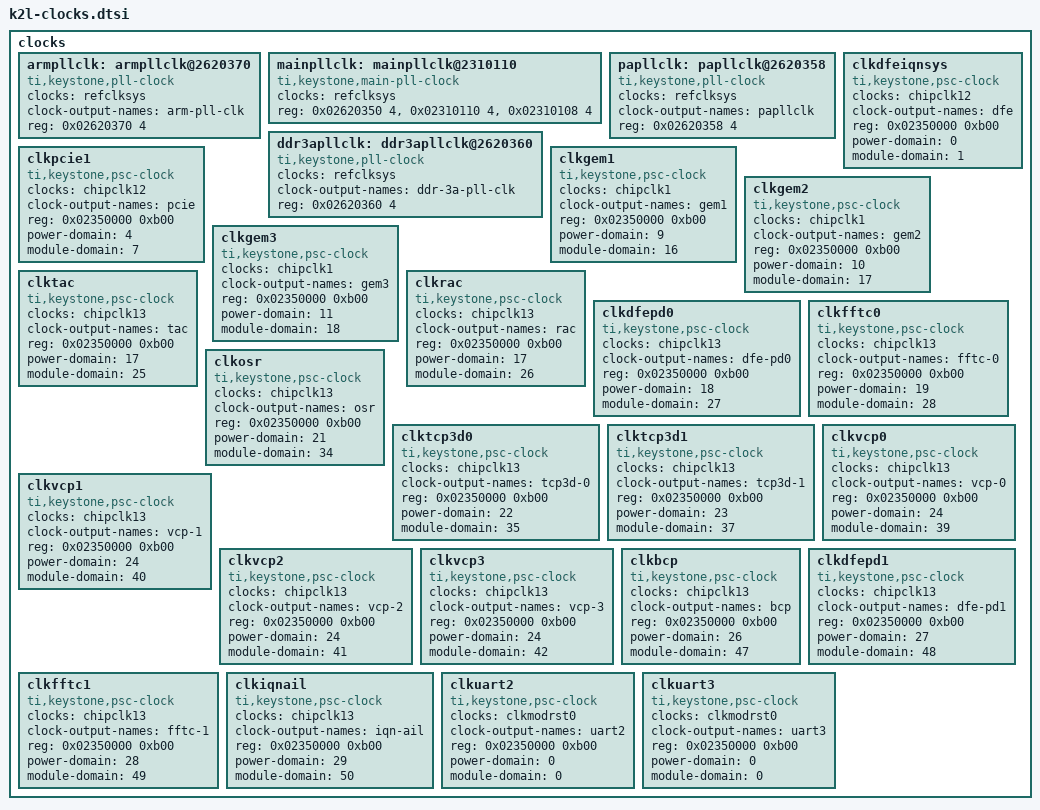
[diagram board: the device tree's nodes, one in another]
/*
 * Copyright 2013-2014 Texas Instruments, Inc.
 *
 * Keystone 2 lamarr SoC clock nodes
 *
 * This program is free software; you can redistribute it and/or modify
 * it under the terms of the GNU General Public License version 2 as
 * published by the Free Software Foundation.
 */

clocks {
	armpllclk: armpllclk@2620370 {
		#clock-cells = <0>;
		compatible = "ti,keystone,pll-clock";
		clocks = <&refclksys>;
		clock-output-names = "arm-pll-clk";
		reg = <0x02620370 4>;
		reg-names = "control";
	};

	mainpllclk: mainpllclk@2310110 {
		#clock-cells = <0>;
		compatible = "ti,keystone,main-pll-clock";
		clocks = <&refclksys>;
		reg = <0x02620350 4>, <0x02310110 4>, <0x02310108 4>;
		reg-names = "control", "multiplier", "post-divider";
	};

	papllclk: papllclk@2620358 {
		#clock-cells = <0>;
		compatible = "ti,keystone,pll-clock";
		clocks = <&refclksys>;
		clock-output-names = "papllclk";
		reg = <0x02620358 4>;
		reg-names = "control";
	};

	ddr3apllclk: ddr3apllclk@2620360 {
		#clock-cells = <0>;
		compatible = "ti,keystone,pll-clock";
		clocks = <&refclksys>;
		clock-output-names = "ddr-3a-pll-clk";
		reg = <0x02620360 4>;
		reg-names = "control";
	};

	clkdfeiqnsys: clkdfeiqnsys {
		#clock-cells = <0>;
		compatible = "ti,keystone,psc-clock";
		clocks = <&chipclk12>;
		clock-output-names = "dfe";
		reg = <0x02350000 0xb00>;
		power-domain = <0>;
		module-domain = <1>;
	};

	clkpcie1: clkpcie1 {
		#clock-cells = <0>;
		compatible = "ti,keystone,psc-clock";
		clocks = <&chipclk12>;
		clock-output-names = "pcie";
		reg = <0x02350000 0xb00>;
		power-domain = <4>;
		module-domain = <7>;
	};

	clkgem1: clkgem1 {
		#clock-cells = <0>;
		compatible = "ti,keystone,psc-clock";
		clocks = <&chipclk1>;
		clock-output-names = "gem1";
		reg = <0x02350000 0xb00>;
		power-domain = <9>;
		module-domain = <16>;
	};

	clkgem2: clkgem2 {
		#clock-cells = <0>;
		compatible = "ti,keystone,psc-clock";
		clocks = <&chipclk1>;
		clock-output-names = "gem2";
		reg = <0x02350000 0xb00>;
		power-domain = <10>;
		module-domain = <17>;
	};

	clkgem3: clkgem3 {
		#clock-cells = <0>;
		compatible = "ti,keystone,psc-clock";
		clocks = <&chipclk1>;
		clock-output-names = "gem3";
		reg = <0x02350000 0xb00>;
		power-domain = <11>;
		module-domain = <18>;
	};

	clktac: clktac {
		#clock-cells = <0>;
		compatible = "ti,keystone,psc-clock";
		clocks = <&chipclk13>;
		clock-output-names = "tac";
		reg = <0x02350000 0xb00>;
		power-domain = <17>;
		module-domain = <25>;
	};

	clkrac: clkrac {
		#clock-cells = <0>;
		compatible = "ti,keystone,psc-clock";
		clocks = <&chipclk13>;
		clock-output-names = "rac";
		reg = <0x02350000 0xb00>;
		power-domain = <17>;
		module-domain = <26>;
	};

	clkdfepd0: clkdfepd0 {
		#clock-cells = <0>;
		compatible = "ti,keystone,psc-clock";
		clocks = <&chipclk13>;
		clock-output-names = "dfe-pd0";
		reg = <0x02350000 0xb00>;
		power-domain = <18>;
		module-domain = <27>;
	};

	clkfftc0: clkfftc0 {
		#clock-cells = <0>;
		compatible = "ti,keystone,psc-clock";
		clocks = <&chipclk13>;
		clock-output-names = "fftc-0";
		reg = <0x02350000 0xb00>;
		power-domain = <19>;
		module-domain = <28>;
	};

	clkosr: clkosr {
		#clock-cells = <0>;
		compatible = "ti,keystone,psc-clock";
		clocks = <&chipclk13>;
		clock-output-names = "osr";
		reg = <0x02350000 0xb00>;
		power-domain = <21>;
		module-domain = <34>;
	};

	clktcp3d0: clktcp3d0 {
		#clock-cells = <0>;
		compatible = "ti,keystone,psc-clock";
		clocks = <&chipclk13>;
		clock-output-names = "tcp3d-0";
		reg = <0x02350000 0xb00>;
		power-domain = <22>;
		module-domain = <35>;
	};

	clktcp3d1: clktcp3d1 {
		#clock-cells = <0>;
		compatible = "ti,keystone,psc-clock";
		clocks = <&chipclk13>;
		clock-output-names = "tcp3d-1";
		reg = <0x02350000 0xb00>;
		power-domain = <23>;
		module-domain = <37>;
	};

	clkvcp0: clkvcp0 {
		#clock-cells = <0>;
		compatible = "ti,keystone,psc-clock";
		clocks = <&chipclk13>;
		clock-output-names = "vcp-0";
		reg = <0x02350000 0xb00>;
		power-domain = <24>;
		module-domain = <39>;
	};

	clkvcp1: clkvcp1 {
		#clock-cells = <0>;
		compatible = "ti,keystone,psc-clock";
		clocks = <&chipclk13>;
		clock-output-names = "vcp-1";
		reg = <0x02350000 0xb00>;
		power-domain = <24>;
		module-domain = <40>;
	};

	clkvcp2: clkvcp2 {
		#clock-cells = <0>;
		compatible = "ti,keystone,psc-clock";
		clocks = <&chipclk13>;
		clock-output-names = "vcp-2";
		reg = <0x02350000 0xb00>;
		power-domain = <24>;
		module-domain = <41>;
	};

	clkvcp3: clkvcp3 {
		#clock-cells = <0>;
		compatible = "ti,keystone,psc-clock";
		clocks = <&chipclk13>;
		clock-output-names = "vcp-3";
		reg = <0x02350000 0xb00>;
		power-domain = <24>;
		module-domain = <42>;
	};

	clkbcp: clkbcp {
		#clock-cells = <0>;
		compatible = "ti,keystone,psc-clock";
		clocks = <&chipclk13>;
		clock-output-names = "bcp";
		reg = <0x02350000 0xb00>;
		power-domain = <26>;
		module-domain = <47>;
	};

	clkdfepd1: clkdfepd1 {
		#clock-cells = <0>;
		compatible = "ti,keystone,psc-clock";
		clocks = <&chipclk13>;
		clock-output-names = "dfe-pd1";
		reg = <0x02350000 0xb00>;
		power-domain = <27>;
		module-domain = <48>;
	};

	clkfftc1: clkfftc1 {
		#clock-cells = <0>;
		compatible = "ti,keystone,psc-clock";
		clocks = <&chipclk13>;
		clock-output-names = "fftc-1";
		reg = <0x02350000 0xb00>;
		power-domain = <28>;
		module-domain = <49>;
	};

	clkiqnail: clkiqnail {
		#clock-cells = <0>;
		compatible = "ti,keystone,psc-clock";
		clocks = <&chipclk13>;
		clock-output-names = "iqn-ail";
		reg = <0x02350000 0xb00>;
		power-domain = <29>;
		module-domain = <50>;
	};

	clkuart2: clkuart2 {
		#clock-cells = <0>;
		compatible = "ti,keystone,psc-clock";
		clocks = <&clkmodrst0>;
		clock-output-names = "uart2";
		reg = <0x02350000 0xb00>;
		power-domain = <0>;
		module-domain = <0>;
	};

	clkuart3: clkuart3 {
		#clock-cells = <0>;
		compatible = "ti,keystone,psc-clock";
		clocks = <&clkmodrst0>;
		clock-output-names = "uart3";
		reg = <0x02350000 0xb00>;
		power-domain = <0>;
		module-domain = <0>;
	};
};
